# PHY6222 register map
File version: 1.0
CPU: CM0 r0p0, little endian, no MPU, no FPU, 2 interrupt priority bits
Registers are 32-bit, read-write, reset 0x0 unless marked. A register's access mark holds for its fields unless they carry their own. Offsets are from the block's base; [hi:lo] are bit positions; {n}, {i} and the like mark numbered series.

## GPIO — General-purpose I/Os
Base 0x48008000
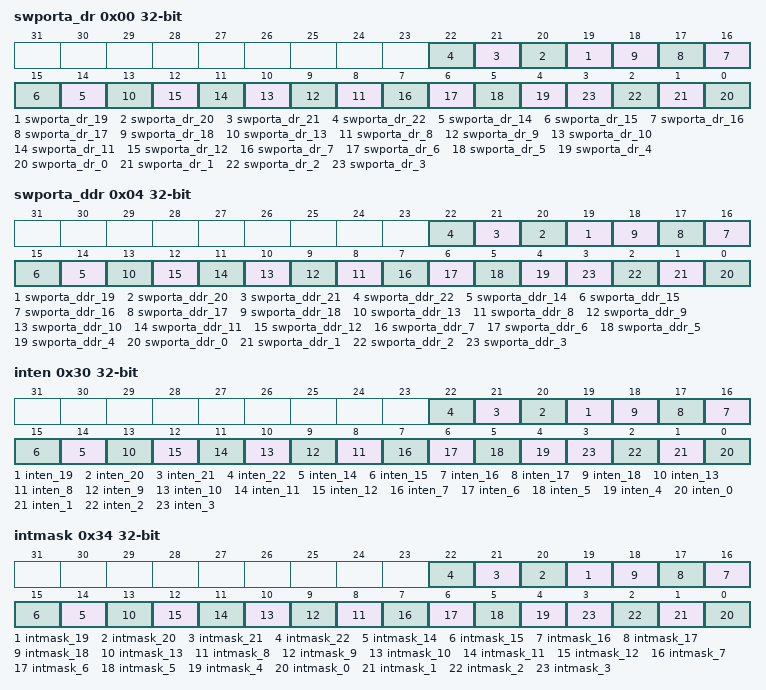
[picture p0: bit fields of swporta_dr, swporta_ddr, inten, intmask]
0x00 swporta_dr — GPIO Data Register (Values)
  [n] swporta_dr_{n} (n=19..22) — GPIO{n+12} value
  [n] swporta_dr_{n} (n=14..18) — GPIO{n+9} value
  [13] swporta_dr_13 — GPIO20 value
  [n] swporta_dr_{n} (n=8..12) — GPIO{n+6} value
  [7] swporta_dr_7 — GPIO11 value
  [6] swporta_dr_6 — GPIO10 value
  [5] swporta_dr_5 — GPIO09 value
  [4] swporta_dr_4 — GPIO07 value
  [n] swporta_dr_{n} (n=0..3) — GPIO{n:02} value
0x04 swporta_ddr — GPIO Direction Register
  [n] swporta_ddr_{n} (n=19..22) — GPIO{n+12} direction
  [n] swporta_ddr_{n} (n=14..18) — GPIO{n+9} direction
  [13] swporta_ddr_13 — GPIO20 direction
  [n] swporta_ddr_{n} (n=8..12) — GPIO{n+6} direction
  [7] swporta_ddr_7 — GPIO11 direction
  [6] swporta_ddr_6 — GPIO10 direction
  [5] swporta_ddr_5 — GPIO09 direction
  [4] swporta_ddr_4 — GPIO07 direction
  [n] swporta_ddr_{n} (n=0..3) — GPIO{n:02} direction
0x08 swporta_ctl — GPIO port A data source
0x30 inten — GPIO interrupt enable
  [n] inten_{n} (n=19..22) — GPIO{n+12} interrupt enable
  [n] inten_{n} (n=14..18) — GPIO{n+9} interrupt enable
  [13] inten_13 — GPIO20 interrupt enable
  [n] inten_{n} (n=8..12) — GPIO{n+6} interrupt enable
  [7] inten_7 — GPIO11 interrupt enable
  [6] inten_6 — GPIO10 interrupt enable
  [5] inten_5 — GPIO09 interrupt enable
  [4] inten_4 — GPIO07 interrupt enable
  [n] inten_{n} (n=0..3) — GPIO{n:02} interrupt enable
0x34 intmask — GPIO interrupt mask
  [n] intmask_{n} (n=19..22) — GPIO{n+12} interrupt mask
  [n] intmask_{n} (n=14..18) — GPIO{n+9} interrupt mask
  [13] intmask_13 — GPIO20 interrupt mask
  [n] intmask_{n} (n=8..12) — GPIO{n+6} interrupt mask
  [7] intmask_7 — GPIO11 interrupt mask
  [6] intmask_6 — GPIO10 interrupt mask
  [5] intmask_5 — GPIO09 interrupt mask
  [4] intmask_4 — GPIO07 interrupt mask
  [n] intmask_{n} (n=0..3) — GPIO{n:02} interrupt mask
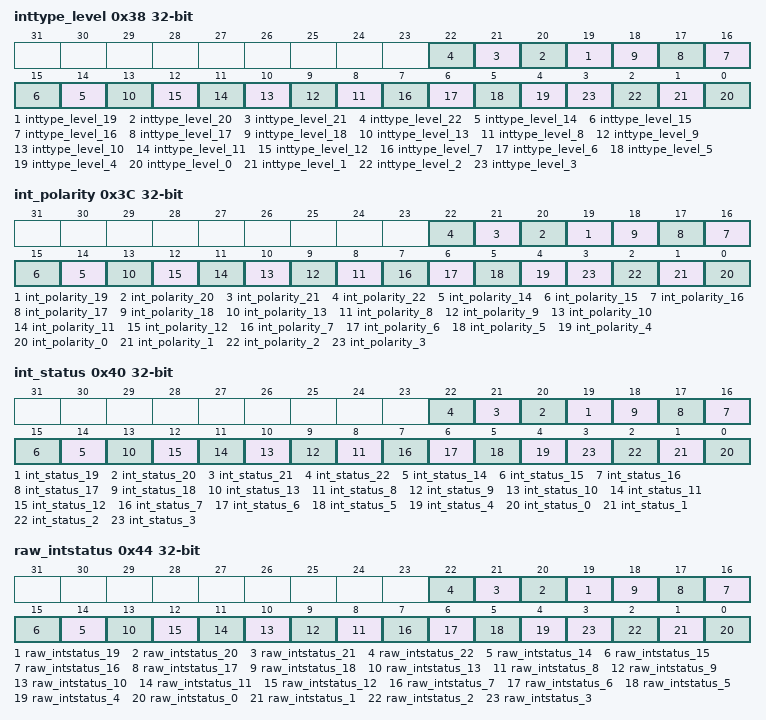
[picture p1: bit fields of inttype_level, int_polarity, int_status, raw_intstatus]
0x38 inttype_level — GPIO interrupt trigger level
  [n] inttype_level_{n} (n=19..22) — GPIO{n+12} interrupt trigger level
  [n] inttype_level_{n} (n=14..18) — GPIO{n+9} interrupt trigger level
  [13] inttype_level_13 — GPIO20 interrupt trigger level
  [n] inttype_level_{n} (n=8..12) — GPIO{n+6} interrupt trigger level
  [7] inttype_level_7 — GPIO11 interrupt trigger level
  [6] inttype_level_6 — GPIO10 interrupt trigger level
  [5] inttype_level_5 — GPIO09 interrupt trigger level
  [4] inttype_level_4 — GPIO07 interrupt trigger level
  [n] inttype_level_{n} (n=0..3) — GPIO{n:02} interrupt trigger level
0x3C int_polarity — GPIO interrupt trigger polarity
  [n] int_polarity_{n} (n=19..22) — GPIO{n+12} interrupt trigger polarity
  [n] int_polarity_{n} (n=14..18) — GPIO{n+9} interrupt trigger polarity
  [13] int_polarity_13 — GPIO20 interrupt trigger polarity
  [n] int_polarity_{n} (n=8..12) — GPIO{n+6} interrupt trigger polarity
  [7] int_polarity_7 — GPIO11 interrupt trigger polarity
  [6] int_polarity_6 — GPIO10 interrupt trigger polarity
  [5] int_polarity_5 — GPIO09 interrupt trigger polarity
  [4] int_polarity_4 — GPIO07 interrupt trigger polarity
  [n] int_polarity_{n} (n=0..3) — GPIO{n:02} interrupt trigger polarity
0x40 int_status ro — GPIO interrupt status
  [n] int_status_{n} (n=19..22) — GPIO{n+12} interrupt status
  [n] int_status_{n} (n=14..18) — GPIO{n+9} interrupt status
  [13] int_status_13 — GPIO20 interrupt status
  [n] int_status_{n} (n=8..12) — GPIO{n+6} interrupt status
  [7] int_status_7 — GPIO11 interrupt status
  [6] int_status_6 — GPIO10 interrupt status
  [5] int_status_5 — GPIO09 interrupt status
  [4] int_status_4 — GPIO07 interrupt status
  [n] int_status_{n} (n=0..3) — GPIO{n:02} interrupt status
0x44 raw_intstatus — GPIO interrupt raw status
  [n] raw_intstatus_{n} (n=19..22) — GPIO{n+12} interrupt raw status
  [n] raw_intstatus_{n} (n=14..18) — GPIO{n+9} interrupt raw status
  [13] raw_intstatus_13 — GPIO20 interrupt raw status
  [n] raw_intstatus_{n} (n=8..12) — GPIO{n+6} interrupt raw status
  [7] raw_intstatus_7 — GPIO11 interrupt raw status
  [6] raw_intstatus_6 — GPIO10 interrupt raw status
  [5] raw_intstatus_5 — GPIO09 interrupt raw status
  [4] raw_intstatus_4 — GPIO07 interrupt raw status
  [n] raw_intstatus_{n} (n=0..3) — GPIO{n:02} interrupt raw status
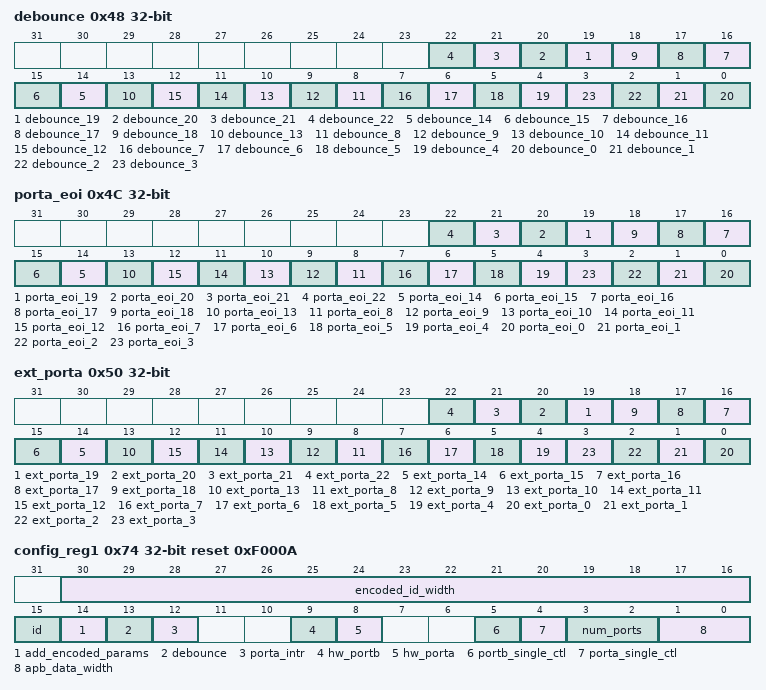
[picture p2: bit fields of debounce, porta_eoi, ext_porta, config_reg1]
0x48 debounce — GPIO debounce
  [n] debounce_{n} (n=19..22) — GPIO{n+12} debounce enable
  [n] debounce_{n} (n=14..18) — GPIO{n+9} debounce enable
  [13] debounce_13 — GPIO20 debounce enable
  [n] debounce_{n} (n=8..12) — GPIO{n+6} debounce enable
  [7] debounce_7 — GPIO11 debounce enable
  [6] debounce_6 — GPIO10 debounce enable
  [5] debounce_5 — GPIO09 debounce enable
  [4] debounce_4 — GPIO07 debounce enable
  [n] debounce_{n} (n=0..3) — GPIO{n:02} debounce enable
0x4C porta_eoi wo — GPIO clear interrupt
  [n] porta_eoi_{n} (n=19..22) — GPIO{n+12} clear interrupt
  [n] porta_eoi_{n} (n=14..18) — GPIO{n+9} clear interrupt
  [13] porta_eoi_13 — GPIO20 clear interrupt
  [n] porta_eoi_{n} (n=8..12) — GPIO{n+6} clear interrupt
  [7] porta_eoi_7 — GPIO11 clear interrupt
  [6] porta_eoi_6 — GPIO10 clear interrupt
  [5] porta_eoi_5 — GPIO09 clear interrupt
  [4] porta_eoi_4 — GPIO07 clear interrupt
  [n] porta_eoi_{n} (n=0..3) — GPIO{n:02} clear interrupt
0x50 ext_porta ro — GPIO input value
  [n] ext_porta_{n} (n=19..22) — GPIO{n+12} input value
  [n] ext_porta_{n} (n=14..18) — GPIO{n+9} input value
  [13] ext_porta_13 — GPIO20 input value
  [n] ext_porta_{n} (n=8..12) — GPIO{n+6} input value
  [7] ext_porta_7 — GPIO11 input value
  [6] ext_porta_6 — GPIO10 input value
  [5] ext_porta_5 — GPIO09 input value
  [4] ext_porta_4 — GPIO07 input value
  [n] ext_porta_{n} (n=0..3) — GPIO{n:02} input value
0x60 ls_sync — GPIO synchronization level
  [0] ext_porta_22 — Synchronization level
0x64 id_code ro — GPIO ID Code
  [15:0] id_code
0x6C ver_id_code ro — GPIO Component Version
  [31:0] component_version
0x70 config_reg2 ro — GPIO component configuration2
0x74 config_reg1 ro reset 0xF000A — GPIO component configuration1
  [30:16] encoded_id_width
  [15] id
  [14] add_encoded_params — Additional Encoded Params
  [13] debounce
  [12] porta_intr — PORTA Interrupt
  [9] hw_portb
  [8] hw_porta
  [5] portb_single_ctl — PORTB single control
  [4] porta_single_ctl — PORTA single control
  [3:2] num_ports — Number of GPIO ports
  [1:0] apb_data_width — Data width of APB connection

## AON
Base 0x4000F000
0x00 PWROFF — Power off register
0x04 PWRSLP — Power sleep register
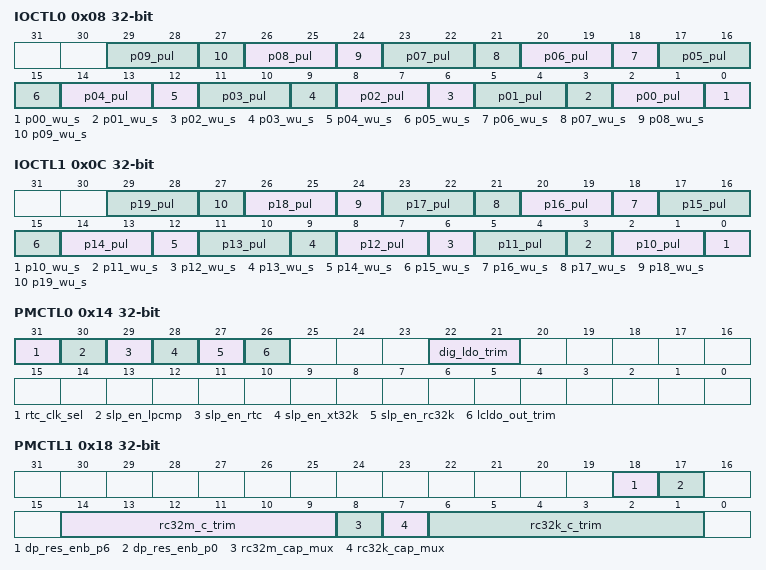
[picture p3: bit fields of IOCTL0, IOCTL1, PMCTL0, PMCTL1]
0x08 IOCTL0 — GPIO pull and wakeup control 0
  [3n+2:3n+1] p{n:02}_pul (n=0..9) — GPIO{n:02} Pull type
  [3n] p{n:02}_wu_s (n=0..9) — GPIO{n:02} wake-up
0x0C IOCTL1 — GPIO pull and wakeup control 1
  [3n-28:3n-29] p{n}_pul (n=10..19) — GPIO{n} Pull type
  [3n-30] p{n}_wu_s (n=10..19) — GPIO{n} wake-up
0x10 IOCTL2 — GPIO retention control
0x14 PMCTL0 — Power management control register 0
  [31] rtc_clk_sel — RTC clock selection
  [30] slp_en_lpcmp — Sleep enable low-power comparator
  [29] slp_en_rtc — RTC sleep enable
  [28] slp_en_xt32k — Sleep enable XT 32.768kHz
  [27] slp_en_rc32k — Sleep enable RC 32.376kHz
  [26] lcldo_out_trim — LDO output trim enable
  [22:21] dig_ldo_trim — LDO Trim value
0x18 PMCTL1 — Power management control register 1
  [18] dp_res_enb_p6 — XT bias enable P6
  [17] dp_res_enb_p0 — XT bias enable P0
  [14:9] rc32m_c_trim — RC 32MHz frequency trim
  [8] rc32m_cap_mux — RC 32MHz cap mux
  [7] rc32k_cap_mux — RC 32.768kHz cap mux
  [6:1] rc32k_c_trim — RC 32.768kHz frequnecy trim
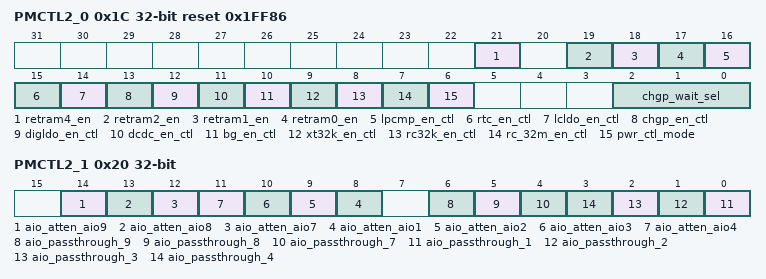
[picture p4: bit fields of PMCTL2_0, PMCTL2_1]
0x1C PMCTL2_0 reset 0x1FF86 — Power management control register 2_0
  [21] retram4_en — Retention RAM4 enable
  [19] retram2_en — Retention RAM2 enable
  [18] retram1_en — Retention RAM1 enable
  [17] retram0_en — Retention RAM0 enable
  [16] lpcmp_en_ctl — LPCMP enable
  [15] rtc_en_ctl — RTC enable
  [14] lcldo_en_ctl — LCLDO enable
  [13] chgp_en_ctl — CHGP enable
  [12] digldo_en_ctl — DIGLDO enable
  [11] dcdc_en_ctl — DCDC enable
  [10] bg_en_ctl — BG enable
  [9] xt32k_en_ctl — XT32K enable
  [8] rc32k_en_ctl — RC32K enable
  [7] rc_32m_en_ctl — RC32M enable
  [6] pwr_ctl_mode — Power control mode
  [2:0] chgp_wait_sel — CHGP Wait selection
0x20 PMCTL2_1 — Power management control register 2_1
  [14] aio_atten_aio9 — Attenuation enable for AIO_9
  [13] aio_atten_aio8 — Attenuation enable for AIO_8
  [12] aio_atten_aio7 — Attenuation enable for AIO_7
  [n+7] aio_atten_aio{n} (n=1..4) — Attenuation enable for AIO_{n}
  [6] aio_passthrough_9 — Passthrough enable for AIO_9
  [5] aio_passthrough_8 — Passthrough enable for AIO_8
  [4] aio_passthrough_7 — Passthrough enable for AIO_7
  [n-1] aio_passthrough_{n} (n=1..4) — Passthrough enable for AIO_{n}
